# STM32MP13xx register map
File version: 1.5
CPU: CA7 r0p0, little endian, MPU, FPU, 4 interrupt priority bits
Registers are 32-bit, read-write, reset 0x0 unless marked. A register's access mark holds for its fields unless they carry their own. Offsets are from the block's base; [hi:lo] are bit positions; {n}, {i} and the like mark numbered series; 'fields as' and 'values as' point back to an identical list.

## STGENC — STGEN
Base 0x5C008000
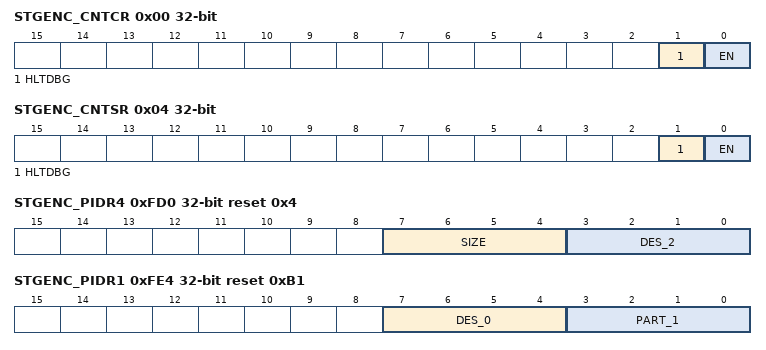
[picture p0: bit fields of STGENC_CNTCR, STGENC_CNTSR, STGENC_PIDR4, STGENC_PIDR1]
0x00 STGENC_CNTCR — STGENC control register
  [1] HLTDBG — halt on debug
    0=do not halt on debug; hltdbg signal into the counter has no effect; 1=halt on debug; when hltdbg is driven high, the count value is held static
  [0] EN — enable
    0=counter disabled and not incrementing; 1=counter enabled and incrementing
0x04 STGENC_CNTSR ro — STGENC status register
  fields as STGENC_CNTCR
0x08 STGENC_CNTCVL — STGENC value lower register
  [31:0] CNTCVL_L_32 — current value of the timestamp counter, lower 32 bits To change the current timestamp value, write the lower 32 bits of the new value to this register before writing the upper 32 bits to STGENC_CNTCVU. The timestamp value is not changed until the STGENC_CNTCVU register is written to.
0x0C STGENC_CNTCVU — STGENC value upper register
  [31:0] CNTCVU_U_32 — current value of the timestamp counter, upper 32 bits To change the current timestamp value, write the lower 32 bits of the new value to STGENC_CNTCVL before writing the upper 32 bits to this register. The 64-bit timestamp value is updated with the value from both writes when this register is written to.
0x20 STGENC_CNTFID0 — STGENC base frequency register
  [31:0] FREQ — frequency in number of ticks per second. It can be specified up to 4 GHz. This register must be programmed to match the clock frequency of the clock input to TSGEN (tsgen_clk), in ticks per second. For example, for a 50 MHz clock, the register value has to be 0x02FAF080.
0xFD0 STGENC_PIDR4 ro reset 0x4 — STGENC peripheral ID4 register
  [7:4] SIZE — always 0b0000 Indicates that the device only occupies 4 Kbytes of memory.
  [3:0] DES_2 — part of designer identification Together PIDR1.DES_0, PIDR2.DES_1, and PIDR4.DES_2 identify the designer of the component. 0b0100 JEDEC continuation code.
{0xFC0+4i} STGENC_PIDR{i} ro (i=5..7) — STGENC peripheral ID{i} register
  [31:0] PIDR{i} — peripheral ID{i}
0xFE0 STGENC_PIDR0 ro reset 0x1 — STGENC peripheral ID0 register
  [7:0] PART_0 — bits[7:0] of the 12-bit part number of the component. The designer of the component assigns this part number.
0xFE4 STGENC_PIDR1 ro reset 0xB1 — STGENC peripheral ID1 register
  [7:4] DES_0 — part of designer identification Together PIDR1.DES_0, PIDR2.DES_1, and PIDR4.DES_2 identify the designer of the component.
  [3:0] PART_1 — Bits[11:8] of the 12-bit part number of the component The designer of the component assigns this part number..
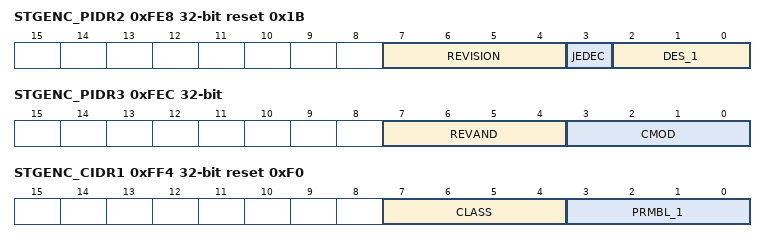
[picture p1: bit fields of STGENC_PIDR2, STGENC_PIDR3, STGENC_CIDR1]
0xFE8 STGENC_PIDR2 ro reset 0x1B — STGENC peripheral ID2 register
  [7:4] REVISION — device revision number
  [3] JEDEC — always 1 Indicates that the JEDEC-assigned designer ID is used.
  [2:0] DES_1 — part of designer identification Together PIDR1.DES_0, PIDR2.DES_1, and PIDR4.DES_2 identify the designer of the component.
0xFEC STGENC_PIDR3 ro — STGENC peripheral ID3 register
  [7:4] REVAND — customer version 0b0000 indicates there are no errata fixes to this component.
  [3:0] CMOD — customer modified Indicates whether the customer has modified the behavior of the component. In most cases, this field is 0b0000 (no modification done). Customers change this value when they make authorized modifications to this component.
0xFF0 STGENC_CIDR0 ro reset 0xD — STGENC component ID0 register
  [7:0] PRMBL_0 — preamble 0 Contains bits[7:0] of the component identification code.
0xFF4 STGENC_CIDR1 ro reset 0xF0 — STGENC component ID1 register
  [7:4] CLASS — class of the component For example, the component can be a ROM table or a generic CoreSight SoC-400 component. Contains bits[15:12] of the component identification code. 0b1111 Indicates the component is a CoreSight SoC-400 component.
  [3:0] PRMBL_1 — preamble 1 Contains bits[11:8] of the component identification code.
0xFF8 STGENC_CIDR2 ro reset 0x50 — STGENC component ID2 register
  [7:0] PRMBL_2 — preamble 2 Contains bits[23:16] of the component identification code
0xFFC STGENC_CIDR3 ro reset 0xB1 — STGENC component ID3 register
  [7:0] PRMBL_3 — preamble 3 Contains bits[31:24] of the component identification code
